# ES32F36xx register map
File version: 1.0
Registers are 32-bit, read-write, reset 0x0 unless marked. A register's access mark holds for its fields unless they carry their own. Offsets are from the block's base; [hi:lo] are bit positions; {n}, {i} and the like mark numbered series; 'fields as' and 'values as' point back to an identical list.

## CALC
Base 0x40085400
0x00 SQRTSR read
  [0] BUSY
0x04 RDCND
  [31:0] RADICAND
0x08 SQRTRES read
  [15:0] RESULT
0x20 DIVDR
  [31:0] DIVD
0x24 DIVSR
  [31:0] DIVS
0x28 DIVQR read
  [31:0] DIVQ
0x2C DIVRR read
  [31:0] DIVS
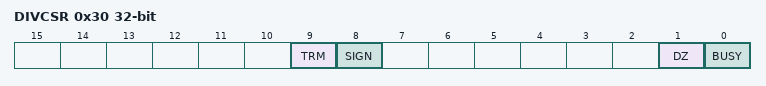
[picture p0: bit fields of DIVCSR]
0x30 DIVCSR read
  [9] TRM rw, [8] SIGN rw, [1] DZ, [0] BUSY

## CRC
Base 0x40085000
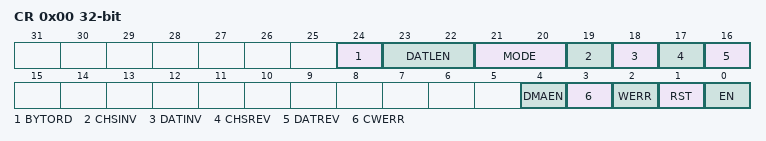
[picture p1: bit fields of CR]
0x00 CR
  [24] BYTORD, [23:22] DATLEN, [21:20] MODE, [19] CHSINV, [18] DATINV, [17] CHSREV, [16] DATREV, [4] DMAEN, [3] CWERR write1, [2] WERR read, [1] RST write1, [0] EN
0x04 DATA
0x08 SEED reset 0xFFFFFFFF
0x0C CHECKSUM read

## CRYPT
Base 0x40085800
{0x0+4i} DATA{i} (i=0..3)
{0x10+4i} KEY{i} (i=0..7)
0x30 IV0
0x34 IV1
0x38 IV2
  [31:0] IV8
0x3C IV3
0x40 RES0 read
0x44 RES1 read
0x48 RES2 read
  [31:0] RES8
0x4C RES3 read
  [31:0] RESx
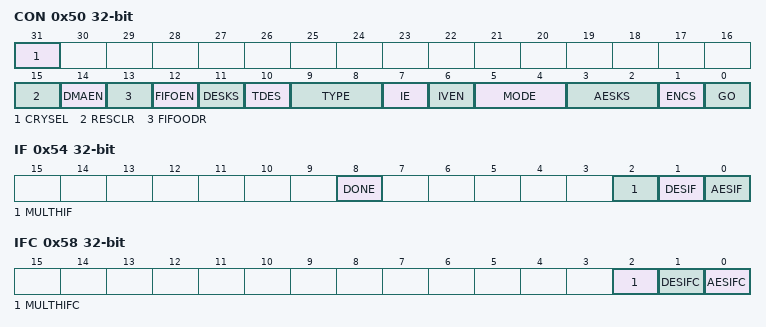
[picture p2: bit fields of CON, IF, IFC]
0x50 CON write1
  [31] CRYSEL rw, [15] RESCLR, [14] DMAEN rw, [13] FIFOODR rw, [12] FIFOEN rw, [11] DESKS rw, [10] TDES rw, [9:8] TYPE rw, [7] IE rw, [6] IVEN rw, [5:4] MODE rw, [3:2] AESKS rw, [1] ENCS rw, [0] GO
0x54 IF read
  [8] DONE, [2] MULTHIF, [1] DESIF, [0] AESIF
0x58 IFC write1
  [2] MULTHIFC, [1] DESIFC, [0] AESIFC
0x5C FIFO

## CAN0
Base 0x4000B000
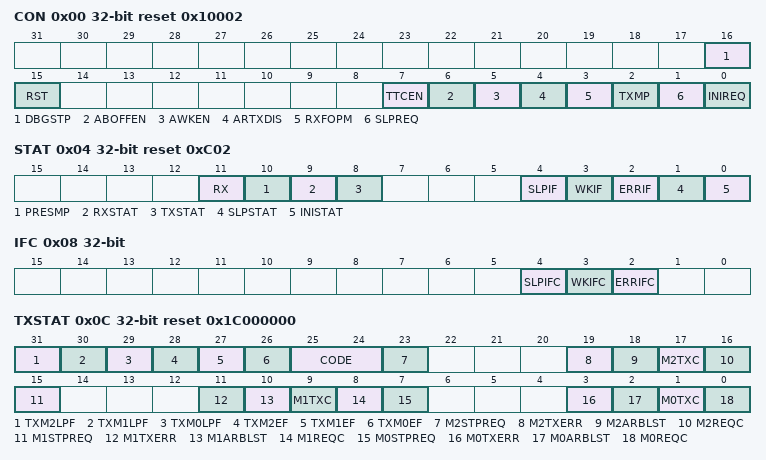
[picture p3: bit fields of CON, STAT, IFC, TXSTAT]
0x00 CON reset 0x10002
  [16] DBGSTP, [15] RST, [7] TTCEN, [6] ABOFFEN, [5] AWKEN, [4] ARTXDIS, [3] RXFOPM, [2] TXMP, [1] SLPREQ, [0] INIREQ
0x04 STAT read reset 0xC02
  [11] RX, [10] PRESMP, [9] RXSTAT, [8] TXSTAT, [4] SLPIF, [3] WKIF, [2] ERRIF, [1] SLPSTAT, [0] INISTAT
0x08 IFC write1
  [4] SLPIFC, [3] WKIFC, [2] ERRIFC
0x0C TXSTAT read reset 0x1C000000
  [31] TXM2LPF, [30] TXM1LPF, [29] TXM0LPF, [28] TXM2EF, [27] TXM1EF, [26] TXM0EF, [25:24] CODE, [23] M2STPREQ rw, [19] M2TXERR, [18] M2ARBLST, [17] M2TXC, [16] M2REQC, [15] M1STPREQ rw, [11] M1TXERR, [10] M1ARBLST, [9] M1TXC, [8] M1REQC, [7] M0STPREQ rw, [3] M0TXERR, [2] M0ARBLST, [1] M0TXC, [0] M0REQC
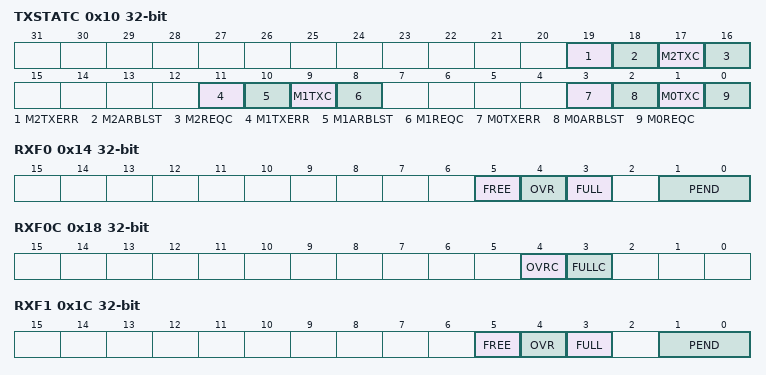
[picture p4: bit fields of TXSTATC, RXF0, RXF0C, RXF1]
0x10 TXSTATC write1
  [19] M2TXERR, [18] M2ARBLST, [17] M2TXC, [16] M2REQC, [11] M1TXERR, [10] M1ARBLST, [9] M1TXC, [8] M1REQC, [3] M0TXERR, [2] M0ARBLST, [1] M0TXC, [0] M0REQC
0x14 RXF0 read
  [5] FREE rw, [4] OVR, [3] FULL, [1:0] PEND
0x18 RXF0C write1
  [4] OVRC, [3] FULLC
0x1C RXF1 read
  [5] FREE rw, [4] OVR, [3] FULL, [1:0] PEND
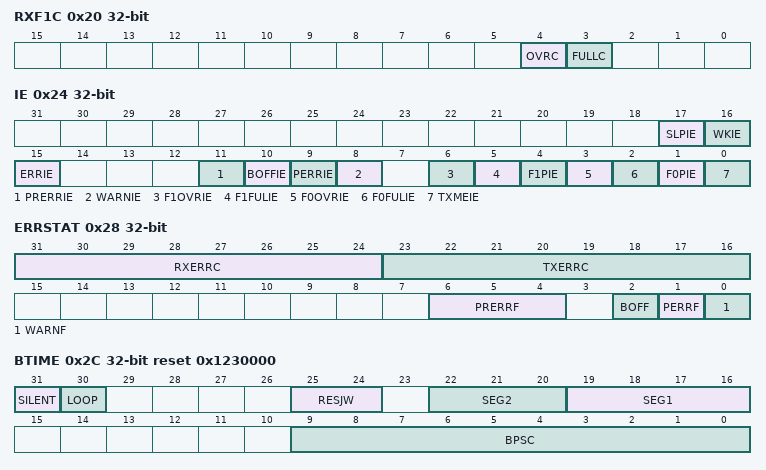
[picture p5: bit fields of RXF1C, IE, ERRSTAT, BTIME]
0x20 RXF1C write1
  [4] OVRC, [3] FULLC
0x24 IE
  [17] SLPIE, [16] WKIE, [15] ERRIE, [11] PRERRIE, [10] BOFFIE, [9] PERRIE, [8] WARNIE, [6] F1OVRIE, [5] F1FULIE, [4] F1PIE, [3] F0OVRIE, [2] F0FULIE, [1] F0PIE, [0] TXMEIE
0x28 ERRSTAT read
  [31:24] RXERRC, [23:16] TXERRC, [6:4] PRERRF rw, [2] BOFF, [1] PERRF, [0] WARNF
0x2C BTIME reset 0x1230000
  [31] SILENT, [30] LOOP, [25:24] RESJW, [22:20] SEG2, [19:16] SEG1, [9:0] BPSC
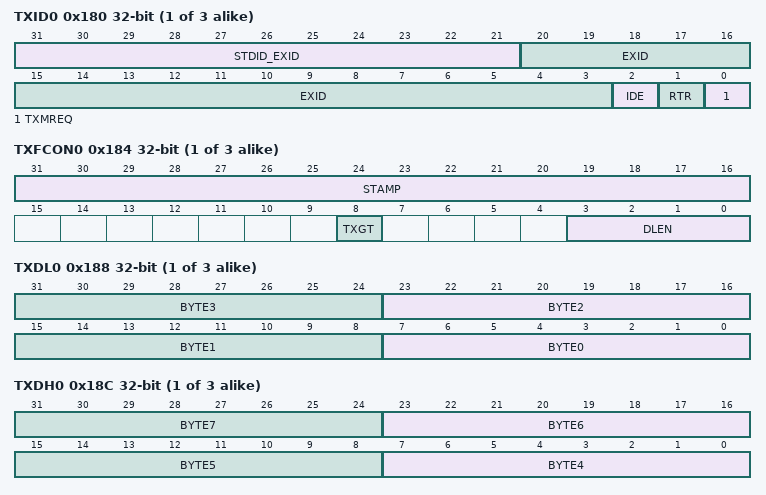
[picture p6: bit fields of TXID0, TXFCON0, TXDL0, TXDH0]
{0x180+0x10*i} TXID{i} (i=0..2)
  [31:21] STDID_EXID, [20:3] EXID, [2] IDE, [1] RTR, [0] TXMREQ
{0x184+0x10*i} TXFCON{i} (i=0..2)
  [31:16] STAMP, [8] TXGT, [3:0] DLEN
{0x188+0x10*i} TXDL{i} (i=0..2)
  [8n+7:8n] BYTE{n} (n=0..3)
{0x18C+0x10*i} TXDH{i} (i=0..2)
  [8n-25:8n-32] BYTE{n} (n=4..7)
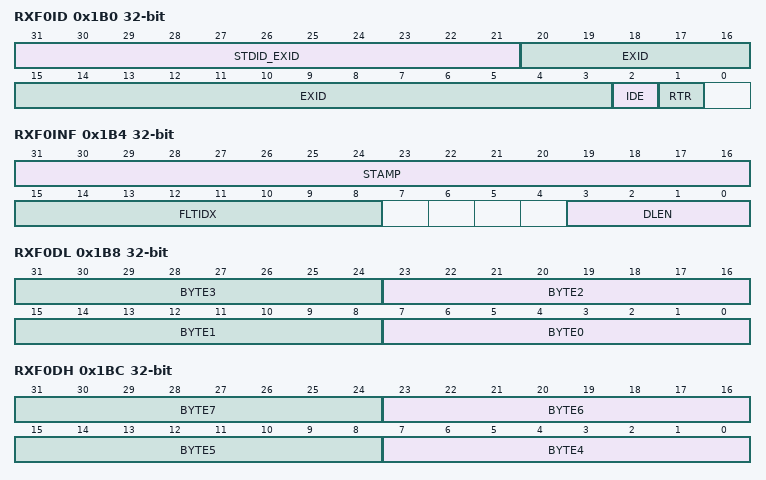
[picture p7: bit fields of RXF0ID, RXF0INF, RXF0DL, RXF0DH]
0x1B0 RXF0ID read
  [31:21] STDID_EXID, [20:3] EXID, [2] IDE, [1] RTR
0x1B4 RXF0INF read
  [31:16] STAMP, [15:8] FLTIDX, [3:0] DLEN
0x1B8 RXF0DL read
  [8n+7:8n] BYTE{n} (n=0..3)
0x1BC RXF0DH read
  [8n-25:8n-32] BYTE{n} (n=4..7)
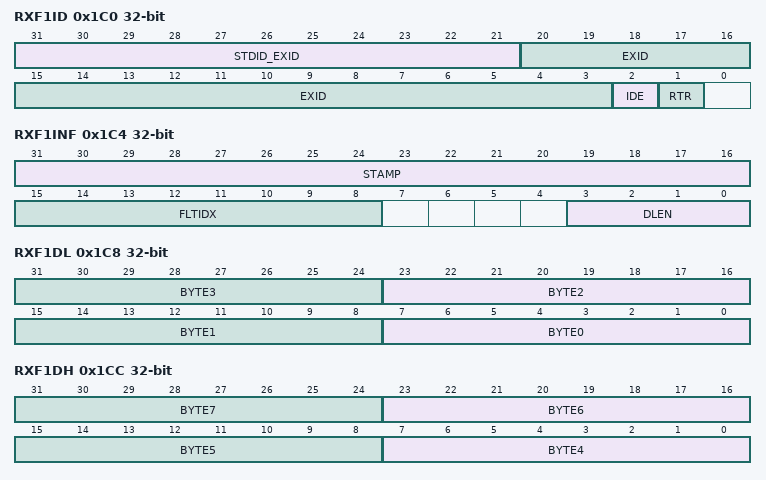
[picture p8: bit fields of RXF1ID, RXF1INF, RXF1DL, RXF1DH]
0x1C0 RXF1ID read
  [31:21] STDID_EXID, [20:3] EXID, [2] IDE, [1] RTR
0x1C4 RXF1INF read
  [31:16] STAMP, [15:8] FLTIDX, [3:0] DLEN
0x1C8 RXF1DL read
  [8n+7:8n] BYTE{n} (n=0..3)
0x1CC RXF1DH read
  [8n-25:8n-32] BYTE{n} (n=4..7)
0x200 FLTCON reset 0x2A1C0E01
  [0] FLTINI
0x204 FLTM
  [13:0] MOD
0x20C FLTWS
  [13:0] SEL
0x214 FLTAS
  [13:0] ASSIGN
0x21C FLTGO
  [13:0] GO
{0x240+8i} FLT{i}R1 (i=0..13)
  [31:0] FLTB
{0x244+8i} FLT{i}R2 (i=0..13)
  [31:0] FLTB

## UART0
Base 0x40004000
Same registers: UART1 0x40004400, UART2 0x40004800, UART3 0x40004C00, UART4 0x40005000, UART5 0x40005400
0x00 RXBUF read
  [8:0] RXBUF
0x04 TXBUF
  [8:0] TXBUF
0x08 BRR
  [15:0] BRR
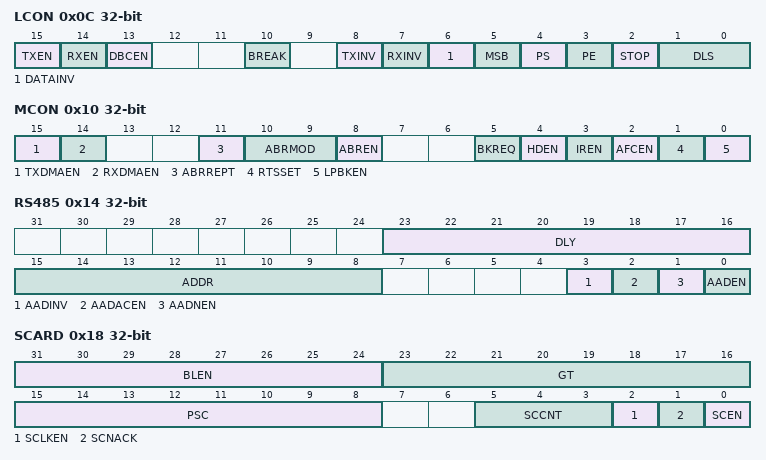
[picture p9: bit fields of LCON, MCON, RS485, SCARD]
0x0C LCON
  [15] TXEN, [14] RXEN, [13] DBCEN, [10] BREAK, [8] TXINV, [7] RXINV, [6] DATAINV, [5] MSB, [4] PS, [3] PE, [2] STOP, [1:0] DLS
0x10 MCON
  [15] TXDMAEN, [14] RXDMAEN, [11] ABRREPT, [10:9] ABRMOD, [8] ABREN, [5] BKREQ write, [4] HDEN, [3] IREN, [2] AFCEN, [1] RTSSET, [0] LPBKEN
0x14 RS485
  [23:16] DLY, [15:8] ADDR, [3] AADINV, [2] AADACEN, [1] AADNEN, [0] AADEN
0x18 SCARD
  [31:24] BLEN, [23:16] GT, [15:8] PSC, [5:3] SCCNT, [2] SCLKEN, [1] SCNACK, [0] SCEN
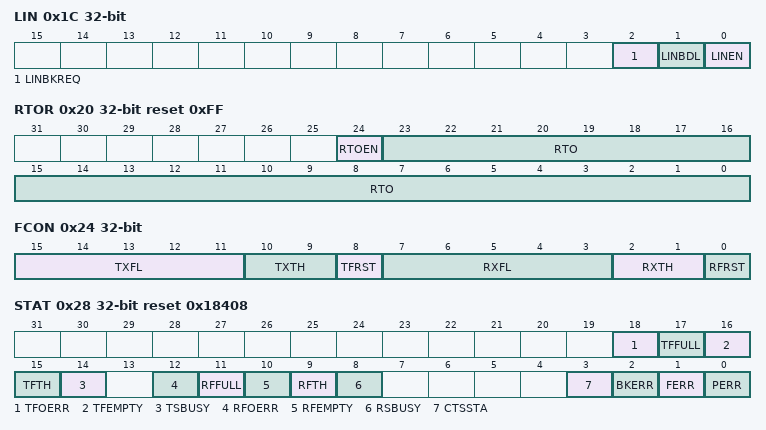
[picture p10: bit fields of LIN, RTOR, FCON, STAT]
0x1C LIN
  [2] LINBKREQ write1, [1] LINBDL, [0] LINEN
0x20 RTOR reset 0xFF
  [24] RTOEN, [23:0] RTO
0x24 FCON write1
  [15:11] TXFL read, [10:9] TXTH rw, [8] TFRST, [7:3] RXFL read, [2:1] RXTH rw, [0] RFRST
0x28 STAT read reset 0x18408
  [18] TFOERR, [17] TFFULL, [16] TFEMPTY, [15] TFTH, [14] TSBUSY, [12] RFOERR, [11] RFFULL, [10] RFEMPTY, [9] RFTH, [8] RSBUSY, [3] CTSSTA, [2] BKERR, [1] FERR, [0] PERR
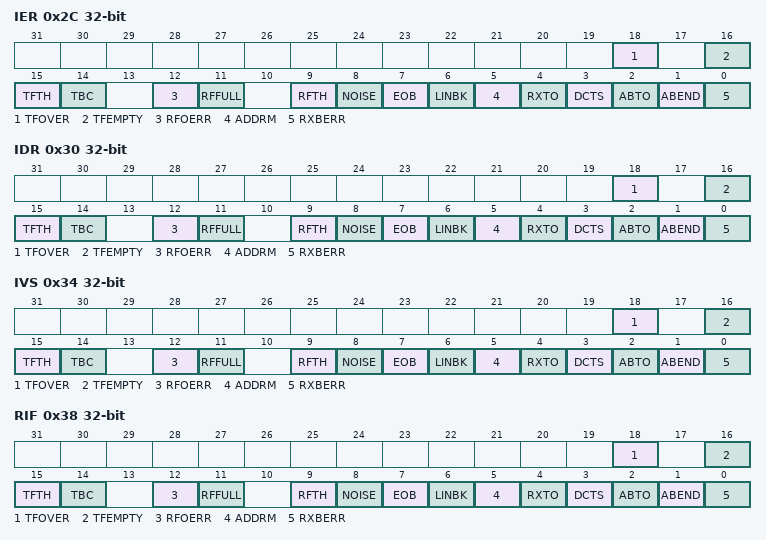
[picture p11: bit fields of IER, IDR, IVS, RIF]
0x2C IER write1
  [18] TFOVER, [16] TFEMPTY, [15] TFTH, [14] TBC, [12] RFOERR, [11] RFFULL, [9] RFTH, [8] NOISE, [7] EOB, [6] LINBK, [5] ADDRM, [4] RXTO, [3] DCTS, [2] ABTO, [1] ABEND, [0] RXBERR
0x30 IDR write1
  fields as IER
0x34 IVS read
  fields as IER
0x38 RIF read
  fields as IER
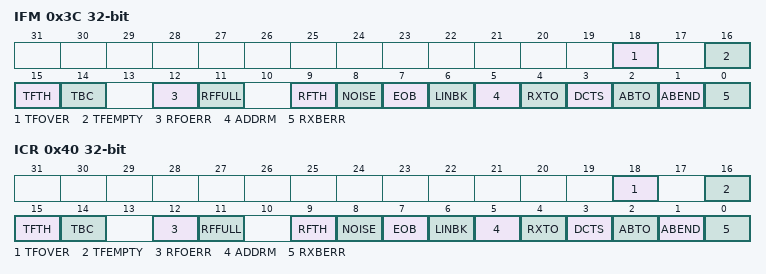
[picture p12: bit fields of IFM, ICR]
0x3C IFM read
  fields as IER
0x40 ICR clear-write1
  fields as IER
